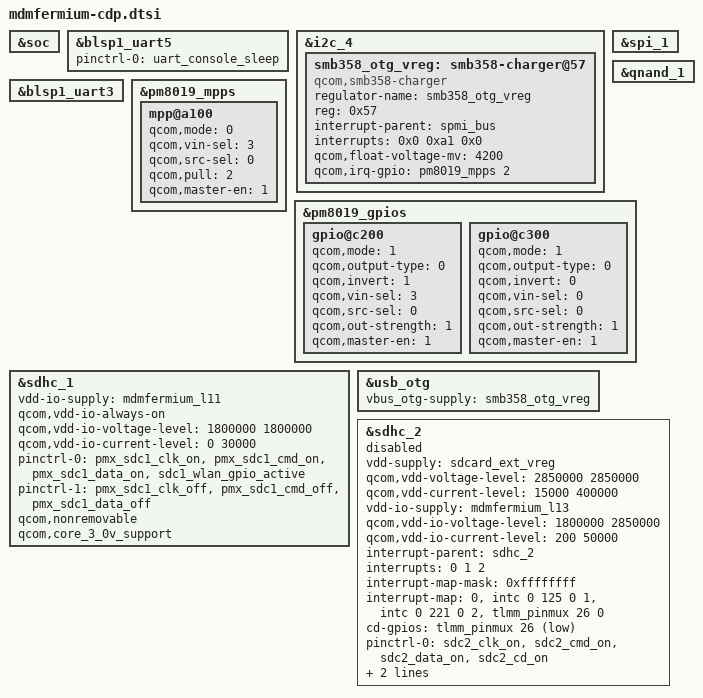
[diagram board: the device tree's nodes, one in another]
/*
 * Copyright (c) 2015, The Linux Foundation. All rights reserved.
 *
 * This program is free software; you can redistribute it and/or modify
 * it under the terms of the GNU General Public License version 2 and
 * only version 2 as published by the Free Software Foundation.
 *
 * This program is distributed in the hope that it will be useful,
 * but WITHOUT ANY WARRANTY; without even the implied warranty of
 * MERCHANTABILITY or FITNESS FOR A PARTICULAR PURPOSE.  See the
 * GNU General Public License for more details.
 */

#include "mdmfermium.dtsi"
#include "mdmfermium-pinctrl.dtsi"

&soc {
};

&blsp1_uart5 {
	status = "ok";
	pinctrl-names = "default";
	pinctrl-0 = <&uart_console_sleep>;
};

&i2c_4 {
	status = "ok";
};

&spi_1 {
	status = "ok";
};

&blsp1_uart3 {
	status = "ok";
};

&qnand_1 {
	status = "ok";
};

/* MPP pin 2 configs for SMB358 interrupt line */
&pm8019_mpps {
	mpp@a100 {
		qcom,mode = <0>;	/* Digital input */
		qcom,vin-sel = <3>;	/* 1.8V (L11) */
		qcom,src-sel = <0>;	/* QPNP_PIN_SEL_FUNC_CONSTANT */
		qcom,pull = <2>;	/* PULL UP 10KOHM */
		qcom,master-en = <1>;
	};
};

/* PMIC gpio for wlan power supply */
&pm8019_gpios {
	gpio@c200 {
		qcom,mode = <1>;		/* Digital output */
		qcom,output-type = <0>;		/* CMOS logic */
		qcom,invert = <1>;		/* Output high */
		qcom,vin-sel = <3>;		/* VPH_PWR */
		qcom,src-sel = <0>;		/* Constant */
		qcom,out-strength = <1>;	/* High drive strength */
		qcom,master-en = <1>;		/* Enable GPIO */
		status = "okay";
	};
};

&pm8019_gpios {
	gpio@c300 { /* GPIO 4 */
		qcom,mode = <1>;		/* Digital output */
		qcom,output-type = <0>;		/* CMOS logic */
		qcom,invert = <0>;		/* Output high */
		qcom,vin-sel = <0>;		/* VPH_PWR */
		qcom,src-sel = <0>;		/* GPIO */
		qcom,out-strength = <1>;	/* Low drive strength */
		qcom,master-en = <1>;		/* Enable GPIO */
	};
};

&i2c_4 {
	/* SMB358 charger configuration */
	smb358_otg_vreg: smb358-charger@57 {
		compatible = "qcom,smb358-charger";
		regulator-name = "smb358_otg_vreg";
		reg = <0x57>;
		interrupt-parent = <&spmi_bus>;
		interrupts = <0x0 0xa1 0x0>; /* PMIC MPP 2 */
		qcom,float-voltage-mv = <4200>;
		qcom,irq-gpio = <&pm8019_mpps 2 0>;
	};
};

&sdhc_1 {
	vdd-io-supply = <&mdmfermium_l11>;
	qcom,vdd-io-always-on;
	qcom,vdd-io-voltage-level = <1800000 1800000>;
	qcom,vdd-io-current-level = <0 30000>;

	pinctrl-names = "active", "sleep";
	pinctrl-0 = <&pmx_sdc1_clk_on &pmx_sdc1_cmd_on &pmx_sdc1_data_on
						&sdc1_wlan_gpio_active>;
	pinctrl-1 = <&pmx_sdc1_clk_off &pmx_sdc1_cmd_off &pmx_sdc1_data_off>;
	qcom,nonremovable;
	qcom,core_3_0v_support;
	status = "ok";
};

&usb_otg {
	vbus_otg-supply = <&smb358_otg_vreg>;
};

&sdhc_2 {
	vdd-supply = <&sdcard_ext_vreg>;
	qcom,vdd-voltage-level = <2850000 2850000>;
	qcom,vdd-current-level = <15000 400000>;

	vdd-io-supply = <&mdmfermium_l13>;
	qcom,vdd-io-voltage-level = <1800000 2850000>;
	qcom,vdd-io-current-level = <200 50000>;

	#address-cells = <0>;
	interrupt-parent = <&sdhc_2>;
	interrupts = <0 1 2>;
	#interrupt-cells = <1>;
	interrupt-map-mask = <0xffffffff>;
	interrupt-map = <0 &intc 0 125 0
			1 &intc 0 221 0
			2 &tlmm_pinmux 26 0>;
	interrupt-names = "hc_irq", "pwr_irq", "status_irq";
	cd-gpios = <&tlmm_pinmux 26 0x1>;

	pinctrl-names = "active", "sleep";
	pinctrl-0 = <&sdc2_clk_on &sdc2_cmd_on &sdc2_data_on &sdc2_cd_on>;
	pinctrl-1 = <&sdc2_clk_off &sdc2_cmd_off &sdc2_data_off>;

	status = "disabled";
};
